AUTOSAR XML (schema 4.0)
package /BcmSystem/DataTypes
  4 x impl type:
    DataArray_Horn_U8: category=ARRAY
      element Horn_Slave_U8: category=VALUE, array-size=16, base-type=uint8
    HORN_T_CAN_BeepCmdOnOff: category=VALUE, base-type=uint8, compu {0=HORN_NOCMD, 1=HORN_OFF, 2=HORN_ON}
    HORN_T_CAN_CtrlTraceBack: category=VALUE, base-type=uint8, compu {0=HORN_NOTACTIVE, 1=HORN_GROUP1, 2=HORN_GROUP2, 3=HORN_GROUP3}
    Horn_SignalGroup_HornBeepCmd: category=STRUCTURE
      element HornBeepCmd_OnOff: implementation-data-type=uint8
      element HornBeepCmd_Templet: implementation-data-type=uint8
package /BcmSystem/PortInterfaces
  sender receiver interface IF_Horn_Templet1
    data u8_Signal: type=uint8, init-value=0
  client server interface IF_Horn_Templet2
    operation StartHornByTemplet_Operation
      arg templet: type=uint8, direction=IN
      arg ReturnCode: type=uint8, direction=OUT
    operation StopHornByTemplet_Operation
      arg templet: type=uint8, direction=IN
      arg ReturnCode: type=uint8, direction=OUT
  sender receiver interface VMM_VehModeSt
    data u8_Signal: type=uint8
package /BcmSystem/SwComponentTypes
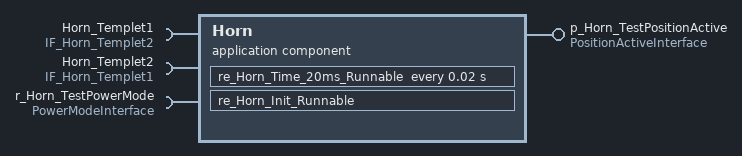
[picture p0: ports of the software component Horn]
  application sw component type Horn
    require port Horn_Templet1: required-interface=IF_Horn_Templet2
    require port Horn_Templet2: required-interface=IF_Horn_Templet1
    provide port p_Horn_TestPositionActive: provided-interface=PositionActiveInterface
    require port r_Horn_TestPowerMode: nonqueued-receiver-com-spec{data-element=PowerMode, enable-update=true}, required-interface=PowerModeInterface
    behavior Horn_IB: handle-termination-and-restart=NO-SUPPORT
      init event ie_Horn_Init_Runnable: start-on-event=re_Horn_Init_Runnable
      timing event te_Horn_Time_20ms_Runnable: start-on-event=re_Horn_Time_20ms_Runnable, period=0.02
      runnable re_Horn_Init_Runnable: symbol=Horn_Init_Runnable
      runnable re_Horn_Time_20ms_Runnable: symbol=Horn_Time_20ms_Runnable
package /BcmSystem/SwImplementations
  swc implementation SwcImpHorn: programming-language=C, sw-version=1.0.0, vendor-id=0, behavior=Horn_IB
    code-descriptors:
      code CodeHorn: artifact-descriptors=autosar-engineering-object={short-label=SwSrcHorn, category=SWSRC}
    resource consumption ResourceConHorn
      21 x memory section:
        CODE: sw-addrmethod=CODE
        CONST_16: alignment=16, size=2, sw-addrmethod=CONST
        CONST_32: alignment=32, size=4, sw-addrmethod=CONST
        CONST_8: alignment=8, size=1, sw-addrmethod=CONST
        CONST_BOOLEAN: alignment=BOOLEAN, size=1, sw-addrmethod=CONST
        CONST_UNSPECIFIED: alignment=UNSPECIFIED, size=0, sw-addrmethod=CONST
        VAR_CLEARED_16: alignment=16, size=2, sw-addrmethod=VAR_CLEARED
        VAR_CLEARED_32: alignment=32, size=4, sw-addrmethod=VAR_CLEARED
        VAR_CLEARED_8: alignment=8, size=1, sw-addrmethod=VAR_CLEARED
        VAR_CLEARED_BOOLEAN: alignment=BOOLEAN, size=1, sw-addrmethod=VAR_CLEARED
        VAR_CLEARED_UNSPECIFIED: alignment=UNSPECIFIED, size=0, sw-addrmethod=VAR_CLEARED
        VAR_INIT_16: alignment=16, size=2, sw-addrmethod=VAR_INIT
        VAR_INIT_32: alignment=32, size=4, sw-addrmethod=VAR_INIT
        VAR_INIT_8: alignment=8, size=1, sw-addrmethod=VAR_INIT
        VAR_INIT_BOOLEAN: alignment=BOOLEAN, size=1, sw-addrmethod=VAR_INIT
        VAR_INIT_UNSPECIFIED: alignment=UNSPECIFIED, size=0, sw-addrmethod=VAR_INIT
        VAR_POWER_ON_CLEARED_16: alignment=16, size=2, sw-addrmethod=VAR_POWER_ON_CLEARED
        VAR_POWER_ON_CLEARED_32: alignment=32, size=4, sw-addrmethod=VAR_POWER_ON_CLEARED
        VAR_POWER_ON_CLEARED_8: alignment=8, size=1, sw-addrmethod=VAR_POWER_ON_CLEARED
        VAR_POWER_ON_CLEARED_BOOLEAN: alignment=BOOLEAN, size=1, sw-addrmethod=VAR_POWER_ON_CLEARED
        VAR_POWER_ON_CLEARED_UNSPECIFIED: alignment=UNSPECIFIED, size=0, sw-addrmethod=VAR_POWER_ON_CLEARED
